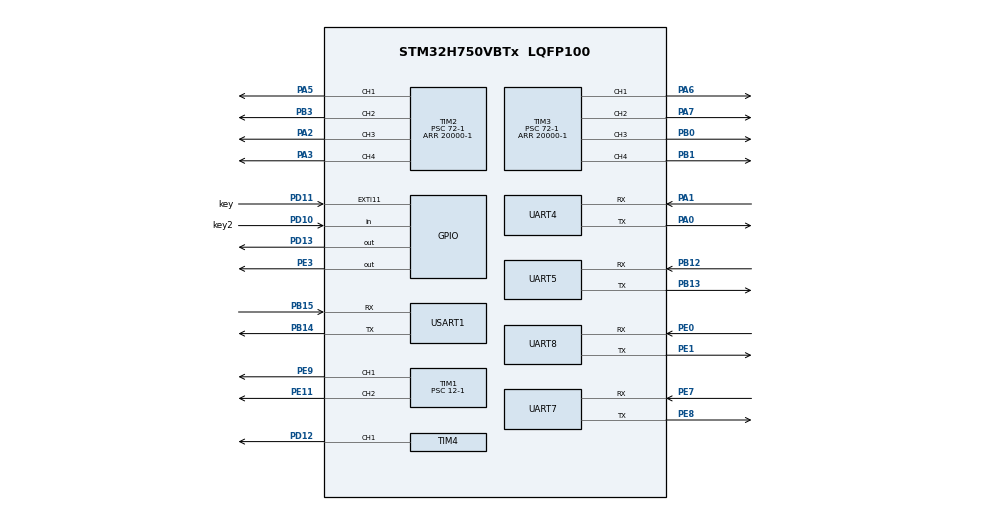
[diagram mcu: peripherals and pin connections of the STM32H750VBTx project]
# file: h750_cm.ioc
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CORTEX_M7.default_mode_Activation=1
Mcu.Family=STM32H7
Mcu.Name=STM32H750VBTx
Mcu.Package=LQFP100
NVIC.EXTI15_10_IRQn=true\:0\:0\:false\:false\:true\:true\:true\:true
NVIC.PriorityGroup=NVIC_PRIORITYGROUP_4
NVIC.USART1_IRQn=true\:0\:0\:false\:false\:true\:true\:true\:true
PA0.Mode=Asynchronous
PA0.Signal=UART4_TX
PA1.Mode=Asynchronous
PA1.Signal=UART4_RX
PA2.Signal=S_TIM2_CH3
PA3.Signal=S_TIM2_CH4
PA5.Signal=S_TIM2_CH1_ETR
PA6.Signal=S_TIM3_CH1
PA7.Signal=S_TIM3_CH2
PB0.Signal=S_TIM3_CH3
PB1.Signal=S_TIM3_CH4
PB12.Mode=Asynchronous
PB12.Signal=UART5_RX
PB13.Mode=Asynchronous
PB13.Signal=UART5_TX
PB14.Mode=Asynchronous
PB14.Signal=USART1_TX
PB15.Mode=Asynchronous
PB15.Signal=USART1_RX
PB3\ (JTDO/TRACESWO).Signal=S_TIM2_CH2
PD10.GPIO_Label=key2
PD10.GPIO_PuPd=GPIO_PULLUP
PD10.Signal=GPIO_Input
PD11.GPIO_Label=key
PD11.GPIO_ModeDefaultEXTI=GPIO_MODE_IT_FALLING
PD11.GPIO_PuPd=GPIO_PULLUP
PD11.Signal=GPXTI11
PD12.Signal=S_TIM4_CH1
PD13.Signal=GPIO_Output
PE0.Mode=Asynchronous
PE0.Signal=UART8_RX
PE1.Mode=Asynchronous
PE1.Signal=UART8_TX
PE11.Signal=S_TIM1_CH2
PE3.Signal=GPIO_Output
PE7.Mode=Asynchronous
PE7.Signal=UART7_RX
PE8.Mode=Asynchronous
PE8.Signal=UART7_TX
PE9.Signal=S_TIM1_CH1
PH0-OSC_IN\ (PH0).Mode=HSE-External-Oscillator
PH0-OSC_IN\ (PH0).Signal=RCC_OSC_IN
PH1-OSC_OUT\ (PH1).Mode=HSE-External-Oscillator
PH1-OSC_OUT\ (PH1).Signal=RCC_OSC_OUT
ProjectManager.HeapSize=0x200
ProjectManager.StackSize=0x400
ProjectManager.TargetToolchain=MDK-ARM V5
RCC.ADCFreq_Value=129000000
RCC.APB1Freq_Value=36000000
RCC.APB2Freq_Value=36000000
RCC.APB3Freq_Value=36000000
RCC.APB4Freq_Value=36000000
RCC.CortexFreq_Value=72000000
RCC.D1CPRE=RCC_SYSCLK_DIV2
RCC.D1PPRE=RCC_APB3_DIV2
RCC.D2PPRE1=RCC_APB1_DIV2
RCC.D2PPRE2=RCC_APB2_DIV2
RCC.D3PPRE=RCC_APB4_DIV2
RCC.DIVM1=4
RCC.DIVN1=18
RCC.HCLKFreq_Value=72000000
RCC.PLL2FRACN=0
RCC.PLL3FRACN=0
RCC.PLLFRACN=0
RCC.SYSCLKFreq_VALUE=144000000
RCC.SYSCLKSource=RCC_SYSCLKSOURCE_PLLCLK
RCC.USBFreq_Value=144000000
SH.S_TIM1_CH1.0=TIM1_CH1,PWM Generation1 CH1
SH.S_TIM1_CH2.0=TIM1_CH2,Output Compare2 CH2
SH.S_TIM2_CH1_ETR.0=TIM2_CH1,PWM Generation1 CH1
SH.S_TIM2_CH2.0=TIM2_CH2,PWM Generation2 CH2
SH.S_TIM2_CH3.0=TIM2_CH3,PWM Generation3 CH3
SH.S_TIM2_CH4.0=TIM2_CH4,PWM Generation4 CH4
SH.S_TIM3_CH1.0=TIM3_CH1,PWM Generation1 CH1
SH.S_TIM3_CH2.0=TIM3_CH2,PWM Generation2 CH2
SH.S_TIM3_CH3.0=TIM3_CH3,PWM Generation3 CH3
SH.S_TIM3_CH4.0=TIM3_CH4,PWM Generation4 CH4
SH.S_TIM4_CH1.0=TIM4_CH1,PWM Generation1 CH1
TIM1.Channel-Output\ Compare2\ CH2=TIM_CHANNEL_2
TIM1.Channel-PWM\ Generation1\ CH1=TIM_CHANNEL_1
TIM1.Period=600-1
TIM1.Prescaler=12-1
TIM2.Channel-PWM\ Generation1\ CH1=TIM_CHANNEL_1
TIM2.Channel-PWM\ Generation2\ CH2=TIM_CHANNEL_2
TIM2.Channel-PWM\ Generation3\ CH3=TIM_CHANNEL_3
TIM2.Channel-PWM\ Generation4\ CH4=TIM_CHANNEL_4
TIM2.Period=20000-1
TIM2.Prescaler=72-1
TIM2.Pulse-PWM\ Generation1\ CH1=0
TIM2.Pulse-PWM\ Generation2\ CH2=0
TIM2.Pulse-PWM\ Generation3\ CH3=0
TIM3.Channel-PWM\ Generation1\ CH1=TIM_CHANNEL_1
TIM3.Channel-PWM\ Generation2\ CH2=TIM_CHANNEL_2
TIM3.Channel-PWM\ Generation3\ CH3=TIM_CHANNEL_3
TIM3.Channel-PWM\ Generation4\ CH4=TIM_CHANNEL_4
TIM3.Period=20000-1
TIM3.Prescaler=72-1
TIM3.Pulse-PWM\ Generation1\ CH1=0
TIM3.Pulse-PWM\ Generation2\ CH2=0
TIM3.Pulse-PWM\ Generation3\ CH3=0
TIM4.Channel-PWM\ Generation1\ CH1=TIM_CHANNEL_1
TIM4.Period=600-1
TIM4.Prescaler=24-1
USART1.VirtualMode-Asynchronous=VM_ASYNC
VP_TIM1_VS_ClockSourceINT.Mode=Internal
VP_TIM2_VS_ClockSourceINT.Mode=Internal
VP_TIM3_VS_ClockSourceINT.Mode=Internal
VP_TIM4_VS_ClockSourceINT.Mode=Internal
board=custom

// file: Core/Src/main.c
/* USER CODE BEGIN Header */
/**
  ******************************************************************************
  * @file           : main.c
  * @brief          : Main program body
  ******************************************************************************
  * @attention
  *
  * Copyright (c) 2024 STMicroelectronics.
  * All rights reserved.
  *
  * This software is licensed under terms that can be found in the LICENSE file
  * in the root directory of this software component.
  * If no LICENSE file comes with this software, it is provided AS-IS.
  *
  ******************************************************************************
  */
/* USER CODE END Header */
#include "main.h"

/* USER CODE BEGIN Includes */
#include "user.h"
/* USER CODE END Includes */

/* USER CODE BEGIN PD */
#include <stdio.h>

/* USER CODE END PD */

TIM_HandleTypeDef htim1;
TIM_HandleTypeDef htim2;
TIM_HandleTypeDef htim3;
TIM_HandleTypeDef htim4;

UART_HandleTypeDef huart4;
UART_HandleTypeDef huart5;
UART_HandleTypeDef huart7;
UART_HandleTypeDef huart8;
UART_HandleTypeDef huart1;

void SystemClock_Config(void);
static void MPU_Config(void);
static void MX_GPIO_Init(void);
static void MX_UART4_Init(void);
static void MX_UART5_Init(void);
static void MX_UART7_Init(void);
static void MX_TIM1_Init(void);
static void MX_TIM2_Init(void);
static void MX_TIM3_Init(void);
static void MX_TIM4_Init(void);
static void MX_UART8_Init(void);
static void MX_USART1_UART_Init(void);

/* USER CODE BEGIN 0 */
int fputc(int ch,FILE *f)
{
//????????1????,???????????
HAL_UART_Transmit(&huart8,(uint8_t *)&ch,1,HAL_MAX_DELAY);
return ch;
}
int fgetc(FILE *f)
{
uint8_t ch;
// ???????? 1????,???????????
HAL_UART_Receive( &huart8,(uint8_t*)&ch,1, HAL_MAX_DELAY );
return ch;
}
/* USER CODE END 0 */

int main(void)
{

  /* MPU Configuration--------------------------------------------------------*/
  MPU_Config();

  /* MCU Configuration--------------------------------------------------------*/

  /* Reset of all peripherals, Initializes the Flash interface and the Systick. */
  HAL_Init();

  /* Configure the system clock */
  SystemClock_Config();

  /* Initialize all configured peripherals */
  MX_GPIO_Init();
  MX_UART4_Init();
  MX_UART5_Init();
  MX_UART7_Init();
  MX_TIM1_Init();
  MX_TIM2_Init();
  MX_TIM3_Init();
  MX_TIM4_Init();
  MX_UART8_Init();
  MX_USART1_UART_Init();
  /* USER CODE BEGIN 2 */
	setup();

	//rm_abandon();

  /* USER CODE END 2 */

  /* Infinite loop */
  while (1)
  {

    /* USER CODE BEGIN 3 */
		//loop();
  }
  /* USER CODE END 3 */
}

void SystemClock_Config(void)
{
  RCC_OscInitTypeDef RCC_OscInitStruct = {0};
  RCC_ClkInitTypeDef RCC_ClkInitStruct = {0};

  /** Supply configuration update enable
  */
  HAL_PWREx_ConfigSupply(PWR_LDO_SUPPLY);

  /** Configure the main internal regulator output voltage
  */
  __HAL_PWR_VOLTAGESCALING_CONFIG(PWR_REGULATOR_VOLTAGE_SCALE3);

  while(!__HAL_PWR_GET_FLAG(PWR_FLAG_VOSRDY)) {}

  /** Initializes the RCC Oscillators according to the specified parameters
  * in the RCC_OscInitTypeDef structure.
  */
  RCC_OscInitStruct.OscillatorType = RCC_OSCILLATORTYPE_HSI;
  RCC_OscInitStruct.HSIState = RCC_HSI_DIV1;
  RCC_OscInitStruct.HSICalibrationValue = RCC_HSICALIBRATION_DEFAULT;
  RCC_OscInitStruct.PLL.PLLState = RCC_PLL_ON;
  RCC_OscInitStruct.PLL.PLLSource = RCC_PLLSOURCE_HSI;
  RCC_OscInitStruct.PLL.PLLM = 4;
  RCC_OscInitStruct.PLL.PLLN = 18;
  RCC_OscInitStruct.PLL.PLLP = 2;
  RCC_OscInitStruct.PLL.PLLQ = 2;
  RCC_OscInitStruct.PLL.PLLR = 2;
  RCC_OscInitStruct.PLL.PLLRGE = RCC_PLL1VCIRANGE_3;
  RCC_OscInitStruct.PLL.PLLVCOSEL = RCC_PLL1VCOWIDE;
  RCC_OscInitStruct.PLL.PLLFRACN = 0;
  if (HAL_RCC_OscConfig(&RCC_OscInitStruct) != HAL_OK)
  {
    Error_Handler();
  }

  /** Initializes the CPU, AHB and APB buses clocks
  */
  RCC_ClkInitStruct.ClockType = RCC_CLOCKTYPE_HCLK|RCC_CLOCKTYPE_SYSCLK
                              |RCC_CLOCKTYPE_PCLK1|RCC_CLOCKTYPE_PCLK2
                              |RCC_CLOCKTYPE_D3PCLK1|RCC_CLOCKTYPE_D1PCLK1;
  RCC_ClkInitStruct.SYSCLKSource = RCC_SYSCLKSOURCE_PLLCLK;
  RCC_ClkInitStruct.SYSCLKDivider = RCC_SYSCLK_DIV2;
  RCC_ClkInitStruct.AHBCLKDivider = RCC_HCLK_DIV1;
  RCC_ClkInitStruct.APB3CLKDivider = RCC_APB3_DIV2;
  RCC_ClkInitStruct.APB1CLKDivider = RCC_APB1_DIV2;
  RCC_ClkInitStruct.APB2CLKDivider = RCC_APB2_DIV2;
  RCC_ClkInitStruct.APB4CLKDivider = RCC_APB4_DIV2;

  if (HAL_RCC_ClockConfig(&RCC_ClkInitStruct, FLASH_LATENCY_1) != HAL_OK)
  {
    Error_Handler();
  }
}

static void MX_TIM1_Init(void)
{

  TIM_ClockConfigTypeDef sClockSourceConfig = {0};
  TIM_MasterConfigTypeDef sMasterConfig = {0};
  TIM_OC_InitTypeDef sConfigOC = {0};
  TIM_BreakDeadTimeConfigTypeDef sBreakDeadTimeConfig = {0};

  htim1.Instance = TIM1;
  htim1.Init.Prescaler = 12-1;
  htim1.Init.CounterMode = TIM_COUNTERMODE_UP;
  htim1.Init.Period = 600-1;
  htim1.Init.ClockDivision = TIM_CLOCKDIVISION_DIV1;
  htim1.Init.RepetitionCounter = 0;
  htim1.Init.AutoReloadPreload = TIM_AUTORELOAD_PRELOAD_DISABLE;
  if (HAL_TIM_Base_Init(&htim1) != HAL_OK)
  {
    Error_Handler();
  }
  sClockSourceConfig.ClockSource = TIM_CLOCKSOURCE_INTERNAL;
  if (HAL_TIM_ConfigClockSource(&htim1, &sClockSourceConfig) != HAL_OK)
  {
    Error_Handler();
  }
  if (HAL_TIM_PWM_Init(&htim1) != HAL_OK)
  {
    Error_Handler();
  }
  if (HAL_TIM_OC_Init(&htim1) != HAL_OK)
  {
    Error_Handler();
  }
  sMasterConfig.MasterOutputTrigger = TIM_TRGO_RESET;
  sMasterConfig.MasterOutputTrigger2 = TIM_TRGO2_RESET;
  sMasterConfig.MasterSlaveMode = TIM_MASTERSLAVEMODE_DISABLE;
  if (HAL_TIMEx_MasterConfigSynchronization(&htim1, &sMasterConfig) != HAL_OK)
  {
    Error_Handler();
  }
  sConfigOC.OCMode = TIM_OCMODE_PWM1;
  sConfigOC.Pulse = 0;
  sConfigOC.OCPolarity = TIM_OCPOLARITY_HIGH;
  sConfigOC.OCNPolarity = TIM_OCNPOLARITY_HIGH;
  sConfigOC.OCFastMode = TIM_OCFAST_DISABLE;
  sConfigOC.OCIdleState = TIM_OCIDLESTATE_RESET;
  sConfigOC.OCNIdleState = TIM_OCNIDLESTATE_RESET;
  if (HAL_TIM_PWM_ConfigChannel(&htim1, &sConfigOC, TIM_CHANNEL_1) != HAL_OK)
  {
    Error_Handler();
  }
  sConfigOC.OCMode = TIM_OCMODE_TIMING;
  if (HAL_TIM_OC_ConfigChannel(&htim1, &sConfigOC, TIM_CHANNEL_2) != HAL_OK)
  {
    Error_Handler();
  }
  sBreakDeadTimeConfig.OffStateRunMode = TIM_OSSR_DISABLE;
  sBreakDeadTimeConfig.OffStateIDLEMode = TIM_OSSI_DISABLE;
  sBreakDeadTimeConfig.LockLevel = TIM_LOCKLEVEL_OFF;
  sBreakDeadTimeConfig.DeadTime = 0;
  sBreakDeadTimeConfig.BreakState = TIM_BREAK_DISABLE;
  sBreakDeadTimeConfig.BreakPolarity = TIM_BREAKPOLARITY_HIGH;
  sBreakDeadTimeConfig.BreakFilter = 0;
  sBreakDeadTimeConfig.Break2State = TIM_BREAK2_DISABLE;
  sBreakDeadTimeConfig.Break2Polarity = TIM_BREAK2POLARITY_HIGH;
  sBreakDeadTimeConfig.Break2Filter = 0;
  sBreakDeadTimeConfig.AutomaticOutput = TIM_AUTOMATICOUTPUT_DISABLE;
  if (HAL_TIMEx_ConfigBreakDeadTime(&htim1, &sBreakDeadTimeConfig) != HAL_OK)
  {
    Error_Handler();
  }
  HAL_TIM_MspPostInit(&htim1);

}

static void MX_TIM2_Init(void)
{

  TIM_ClockConfigTypeDef sClockSourceConfig = {0};
  TIM_MasterConfigTypeDef sMasterConfig = {0};
  TIM_OC_InitTypeDef sConfigOC = {0};

  htim2.Instance = TIM2;
  htim2.Init.Prescaler = 72-1;
  htim2.Init.CounterMode = TIM_COUNTERMODE_UP;
  htim2.Init.Period = 20000-1;
  htim2.Init.ClockDivision = TIM_CLOCKDIVISION_DIV1;
  htim2.Init.AutoReloadPreload = TIM_AUTORELOAD_PRELOAD_DISABLE;
  if (HAL_TIM_Base_Init(&htim2) != HAL_OK)
  {
    Error_Handler();
  }
  sClockSourceConfig.ClockSource = TIM_CLOCKSOURCE_INTERNAL;
  if (HAL_TIM_ConfigClockSource(&htim2, &sClockSourceConfig) != HAL_OK)
  {
    Error_Handler();
  }
  if (HAL_TIM_PWM_Init(&htim2) != HAL_OK)
  {
    Error_Handler();
  }
  sMasterConfig.MasterOutputTrigger = TIM_TRGO_RESET;
  sMasterConfig.MasterSlaveMode = TIM_MASTERSLAVEMODE_DISABLE;
  if (HAL_TIMEx_MasterConfigSynchronization(&htim2, &sMasterConfig) != HAL_OK)
  {
    Error_Handler();
  }
  sConfigOC.OCMode = TIM_OCMODE_PWM1;
  sConfigOC.Pulse = 0;
  sConfigOC.OCPolarity = TIM_OCPOLARITY_HIGH;
  sConfigOC.OCFastMode = TIM_OCFAST_DISABLE;
  if (HAL_TIM_PWM_ConfigChannel(&htim2, &sConfigOC, TIM_CHANNEL_1) != HAL_OK)
  {
    Error_Handler();
  }
  if (HAL_TIM_PWM_ConfigChannel(&htim2, &sConfigOC, TIM_CHANNEL_2) != HAL_OK)
  {
    Error_Handler();
  }
  if (HAL_TIM_PWM_ConfigChannel(&htim2, &sConfigOC, TIM_CHANNEL_3) != HAL_OK)
  {
    Error_Handler();
  }
  if (HAL_TIM_PWM_ConfigChannel(&htim2, &sConfigOC, TIM_CHANNEL_4) != HAL_OK)
  {
    Error_Handler();
  }
  HAL_TIM_MspPostInit(&htim2);

}

static void MX_TIM3_Init(void)
{

  TIM_ClockConfigTypeDef sClockSourceConfig = {0};
  TIM_MasterConfigTypeDef sMasterConfig = {0};
  TIM_OC_InitTypeDef sConfigOC = {0};

  htim3.Instance = TIM3;
  htim3.Init.Prescaler = 72-1;
  htim3.Init.CounterMode = TIM_COUNTERMODE_UP;
  htim3.Init.Period = 20000-1;
  htim3.Init.ClockDivision = TIM_CLOCKDIVISION_DIV1;
  htim3.Init.AutoReloadPreload = TIM_AUTORELOAD_PRELOAD_DISABLE;
  if (HAL_TIM_Base_Init(&htim3) != HAL_OK)
  {
    Error_Handler();
  }
  sClockSourceConfig.ClockSource = TIM_CLOCKSOURCE_INTERNAL;
  if (HAL_TIM_ConfigClockSource(&htim3, &sClockSourceConfig) != HAL_OK)
  {
    Error_Handler();
  }
  if (HAL_TIM_PWM_Init(&htim3) != HAL_OK)
  {
    Error_Handler();
  }
  sMasterConfig.MasterOutputTrigger = TIM_TRGO_RESET;
  sMasterConfig.MasterSlaveMode = TIM_MASTERSLAVEMODE_DISABLE;
  if (HAL_TIMEx_MasterConfigSynchronization(&htim3, &sMasterConfig) != HAL_OK)
  {
    Error_Handler();
  }
  sConfigOC.OCMode = TIM_OCMODE_PWM1;
  sConfigOC.Pulse = 0;
  sConfigOC.OCPolarity = TIM_OCPOLARITY_HIGH;
  sConfigOC.OCFastMode = TIM_OCFAST_DISABLE;
  if (HAL_TIM_PWM_ConfigChannel(&htim3, &sConfigOC, TIM_CHANNEL_1) != HAL_OK)
  {
    Error_Handler();
  }
  if (HAL_TIM_PWM_ConfigChannel(&htim3, &sConfigOC, TIM_CHANNEL_2) != HAL_OK)
  {
    Error_Handler();
  }
  if (HAL_TIM_PWM_ConfigChannel(&htim3, &sConfigOC, TIM_CHANNEL_3) != HAL_OK)
  {
    Error_Handler();
  }
  if (HAL_TIM_PWM_ConfigChannel(&htim3, &sConfigOC, TIM_CHANNEL_4) != HAL_OK)
  {
    Error_Handler();
  }
  HAL_TIM_MspPostInit(&htim3);

}

static void MX_TIM4_Init(void)
{

  TIM_ClockConfigTypeDef sClockSourceConfig = {0};
  TIM_MasterConfigTypeDef sMasterConfig = {0};
  TIM_OC_InitTypeDef sConfigOC = {0};

  htim4.Instance = TIM4;
  htim4.Init.Prescaler = 24-1;
  htim4.Init.CounterMode = TIM_COUNTERMODE_UP;
  htim4.Init.Period = 600-1;
  htim4.Init.ClockDivision = TIM_CLOCKDIVISION_DIV1;
  htim4.Init.AutoReloadPreload = TIM_AUTORELOAD_PRELOAD_DISABLE;
  if (HAL_TIM_Base_Init(&htim4) != HAL_OK)
  {
    Error_Handler();
  }
  sClockSourceConfig.ClockSource = TIM_CLOCKSOURCE_INTERNAL;
  if (HAL_TIM_ConfigClockSource(&htim4, &sClockSourceConfig) != HAL_OK)
  {
    Error_Handler();
  }
  if (HAL_TIM_PWM_Init(&htim4) != HAL_OK)
  {
    Error_Handler();
  }
  sMasterConfig.MasterOutputTrigger = TIM_TRGO_RESET;
  sMasterConfig.MasterSlaveMode = TIM_MASTERSLAVEMODE_DISABLE;
  if (HAL_TIMEx_MasterConfigSynchronization(&htim4, &sMasterConfig) != HAL_OK)
  {
    Error_Handler();
  }
  sConfigOC.OCMode = TIM_OCMODE_PWM1;
  sConfigOC.Pulse = 0;
  sConfigOC.OCPolarity = TIM_OCPOLARITY_HIGH;
  sConfigOC.OCFastMode = TIM_OCFAST_DISABLE;
  if (HAL_TIM_PWM_ConfigChannel(&htim4, &sConfigOC, TIM_CHANNEL_1) != HAL_OK)
  {
    Error_Handler();
  }
  HAL_TIM_MspPostInit(&htim4);

}

static void MX_UART4_Init(void)
{

  huart4.Instance = UART4;
  huart4.Init.BaudRate = 115200;
  huart4.Init.WordLength = UART_WORDLENGTH_8B;
  huart4.Init.StopBits = UART_STOPBITS_1;
  huart4.Init.Parity = UART_PARITY_NONE;
  huart4.Init.Mode = UART_MODE_TX_RX;
  huart4.Init.HwFlowCtl = UART_HWCONTROL_NONE;
  huart4.Init.OverSampling = UART_OVERSAMPLING_16;
  huart4.Init.OneBitSampling = UART_ONE_BIT_SAMPLE_DISABLE;
  huart4.Init.ClockPrescaler = UART_PRESCALER_DIV1;
  huart4.AdvancedInit.AdvFeatureInit = UART_ADVFEATURE_NO_INIT;
  if (HAL_UART_Init(&huart4) != HAL_OK)
  {
    Error_Handler();
  }
  if (HAL_UARTEx_SetTxFifoThreshold(&huart4, UART_TXFIFO_THRESHOLD_1_8) != HAL_OK)
  {
    Error_Handler();
  }
  if (HAL_UARTEx_SetRxFifoThreshold(&huart4, UART_RXFIFO_THRESHOLD_1_8) != HAL_OK)
  {
    Error_Handler();
  }
  if (HAL_UARTEx_DisableFifoMode(&huart4) != HAL_OK)
  {
    Error_Handler();
  }

}

static void MX_UART5_Init(void)
{

  huart5.Instance = UART5;
  huart5.Init.BaudRate = 115200;
  huart5.Init.WordLength = UART_WORDLENGTH_8B;
  huart5.Init.StopBits = UART_STOPBITS_1;
  huart5.Init.Parity = UART_PARITY_NONE;
  huart5.Init.Mode = UART_MODE_TX_RX;
  huart5.Init.HwFlowCtl = UART_HWCONTROL_NONE;
  huart5.Init.OverSampling = UART_OVERSAMPLING_16;
  huart5.Init.OneBitSampling = UART_ONE_BIT_SAMPLE_DISABLE;
  huart5.Init.ClockPrescaler = UART_PRESCALER_DIV1;
  huart5.AdvancedInit.AdvFeatureInit = UART_ADVFEATURE_NO_INIT;
  if (HAL_UART_Init(&huart5) != HAL_OK)
  {
    Error_Handler();
  }
  if (HAL_UARTEx_SetTxFifoThreshold(&huart5, UART_TXFIFO_THRESHOLD_1_8) != HAL_OK)
  {
    Error_Handler();
  }
  if (HAL_UARTEx_SetRxFifoThreshold(&huart5, UART_RXFIFO_THRESHOLD_1_8) != HAL_OK)
  {
    Error_Handler();
  }
  if (HAL_UARTEx_DisableFifoMode(&huart5) != HAL_OK)
  {
    Error_Handler();
  }

}

static void MX_UART7_Init(void)
{

  huart7.Instance = UART7;
  huart7.Init.BaudRate = 115200;
  huart7.Init.WordLength = UART_WORDLENGTH_8B;
  huart7.Init.StopBits = UART_STOPBITS_1;
  huart7.Init.Parity = UART_PARITY_NONE;
  huart7.Init.Mode = UART_MODE_TX_RX;
  huart7.Init.HwFlowCtl = UART_HWCONTROL_NONE;
  huart7.Init.OverSampling = UART_OVERSAMPLING_16;
  huart7.Init.OneBitSampling = UART_ONE_BIT_SAMPLE_DISABLE;
  huart7.Init.ClockPrescaler = UART_PRESCALER_DIV1;
  huart7.AdvancedInit.AdvFeatureInit = UART_ADVFEATURE_NO_INIT;
  if (HAL_UART_Init(&huart7) != HAL_OK)
  {
    Error_Handler();
  }
  if (HAL_UARTEx_SetTxFifoThreshold(&huart7, UART_TXFIFO_THRESHOLD_1_8) != HAL_OK)
  {
    Error_Handler();
  }
  if (HAL_UARTEx_SetRxFifoThreshold(&huart7, UART_RXFIFO_THRESHOLD_1_8) != HAL_OK)
  {
    Error_Handler();
  }
  if (HAL_UARTEx_DisableFifoMode(&huart7) != HAL_OK)
  {
    Error_Handler();
  }

}

static void MX_UART8_Init(void)
{

  huart8.Instance = UART8;
  huart8.Init.BaudRate = 115200;
  huart8.Init.WordLength = UART_WORDLENGTH_8B;
  huart8.Init.StopBits = UART_STOPBITS_1;
  huart8.Init.Parity = UART_PARITY_NONE;
  huart8.Init.Mode = UART_MODE_TX_RX;
  huart8.Init.HwFlowCtl = UART_HWCONTROL_NONE;
  huart8.Init.OverSampling = UART_OVERSAMPLING_16;
  huart8.Init.OneBitSampling = UART_ONE_BIT_SAMPLE_DISABLE;
  huart8.Init.ClockPrescaler = UART_PRESCALER_DIV1;
  huart8.AdvancedInit.AdvFeatureInit = UART_ADVFEATURE_NO_INIT;
  if (HAL_UART_Init(&huart8) != HAL_OK)
  {
    Error_Handler();
  }
  if (HAL_UARTEx_SetTxFifoThreshold(&huart8, UART_TXFIFO_THRESHOLD_1_8) != HAL_OK)
  {
    Error_Handler();
  }
  if (HAL_UARTEx_SetRxFifoThreshold(&huart8, UART_RXFIFO_THRESHOLD_1_8) != HAL_OK)
  {
    Error_Handler();
  }
  if (HAL_UARTEx_DisableFifoMode(&huart8) != HAL_OK)
  {
    Error_Handler();
  }

}

static void MX_USART1_UART_Init(void)
{

  huart1.Instance = USART1;
  huart1.Init.BaudRate = 115200;
  huart1.Init.WordLength = UART_WORDLENGTH_8B;
  huart1.Init.StopBits = UART_STOPBITS_1;
  huart1.Init.Parity = UART_PARITY_NONE;
  huart1.Init.Mode = UART_MODE_TX_RX;
  huart1.Init.HwFlowCtl = UART_HWCONTROL_NONE;
  huart1.Init.OverSampling = UART_OVERSAMPLING_16;
  huart1.Init.OneBitSampling = UART_ONE_BIT_SAMPLE_DISABLE;
  huart1.Init.ClockPrescaler = UART_PRESCALER_DIV1;
  huart1.AdvancedInit.AdvFeatureInit = UART_ADVFEATURE_NO_INIT;
  if (HAL_UART_Init(&huart1) != HAL_OK)
  {
    Error_Handler();
  }
  if (HAL_UARTEx_SetTxFifoThreshold(&huart1, UART_TXFIFO_THRESHOLD_1_8) != HAL_OK)
  {
    Error_Handler();
  }
  if (HAL_UARTEx_SetRxFifoThreshold(&huart1, UART_RXFIFO_THRESHOLD_1_8) != HAL_OK)
  {
    Error_Handler();
  }
  if (HAL_UARTEx_DisableFifoMode(&huart1) != HAL_OK)
  {
    Error_Handler();
  }

}

static void MX_GPIO_Init(void)
{
  GPIO_InitTypeDef GPIO_InitStruct = {0};

  /* GPIO Ports Clock Enable */
  __HAL_RCC_GPIOE_CLK_ENABLE();
  __HAL_RCC_GPIOH_CLK_ENABLE();
  __HAL_RCC_GPIOA_CLK_ENABLE();
  __HAL_RCC_GPIOB_CLK_ENABLE();
  __HAL_RCC_GPIOD_CLK_ENABLE();

  /*Configure GPIO pin Output Level */
  HAL_GPIO_WritePin(GPIOE, GPIO_PIN_3, GPIO_PIN_RESET);

  /*Configure GPIO pin Output Level */
  HAL_GPIO_WritePin(GPIOD, GPIO_PIN_13, GPIO_PIN_RESET);

  /*Configure GPIO pin : PE3 */
  GPIO_InitStruct.Pin = GPIO_PIN_3;
  GPIO_InitStruct.Mode = GPIO_MODE_OUTPUT_PP;
  GPIO_InitStruct.Pull = GPIO_NOPULL;
  GPIO_InitStruct.Speed = GPIO_SPEED_FREQ_LOW;
  HAL_GPIO_Init(GPIOE, &GPIO_InitStruct);

  /*Configure GPIO pin : key2_Pin */
  GPIO_InitStruct.Pin = key2_Pin;
  GPIO_InitStruct.Mode = GPIO_MODE_INPUT;
  GPIO_InitStruct.Pull = GPIO_PULLUP;
  HAL_GPIO_Init(key2_GPIO_Port, &GPIO_InitStruct);

  /*Configure GPIO pin : key_Pin */
  GPIO_InitStruct.Pin = key_Pin;
  GPIO_InitStruct.Mode = GPIO_MODE_IT_FALLING;
  GPIO_InitStruct.Pull = GPIO_PULLUP;
  HAL_GPIO_Init(key_GPIO_Port, &GPIO_InitStruct);

  /*Configure GPIO pin : PD13 */
  GPIO_InitStruct.Pin = GPIO_PIN_13;
  GPIO_InitStruct.Mode = GPIO_MODE_OUTPUT_PP;
  GPIO_InitStruct.Pull = GPIO_NOPULL;
  GPIO_InitStruct.Speed = GPIO_SPEED_FREQ_LOW;
  HAL_GPIO_Init(GPIOD, &GPIO_InitStruct);

  /* EXTI interrupt init*/
  HAL_NVIC_SetPriority(EXTI15_10_IRQn, 0, 0);
  HAL_NVIC_EnableIRQ(EXTI15_10_IRQn);

}

 /* MPU Configuration */

void MPU_Config(void)
{
  MPU_Region_InitTypeDef MPU_InitStruct = {0};

  /* Disables the MPU */
  HAL_MPU_Disable();

  /** Initializes and configures the Region and the memory to be protected
  */
  MPU_InitStruct.Enable = MPU_REGION_ENABLE;
  MPU_InitStruct.Number = MPU_REGION_NUMBER0;
  MPU_InitStruct.BaseAddress = 0x0;
  MPU_InitStruct.Size = MPU_REGION_SIZE_4GB;
  MPU_InitStruct.SubRegionDisable = 0x87;
  MPU_InitStruct.TypeExtField = MPU_TEX_LEVEL0;
  MPU_InitStruct.AccessPermission = MPU_REGION_NO_ACCESS;
  MPU_InitStruct.DisableExec = MPU_INSTRUCTION_ACCESS_DISABLE;
  MPU_InitStruct.IsShareable = MPU_ACCESS_SHAREABLE;
  MPU_InitStruct.IsCacheable = MPU_ACCESS_NOT_CACHEABLE;
  MPU_InitStruct.IsBufferable = MPU_ACCESS_NOT_BUFFERABLE;

  HAL_MPU_ConfigRegion(&MPU_InitStruct);
  /* Enables the MPU */
  HAL_MPU_Enable(MPU_PRIVILEGED_DEFAULT);

}

void Error_Handler(void)
{
  __disable_irq();
  while (1)
  {
  }
}
